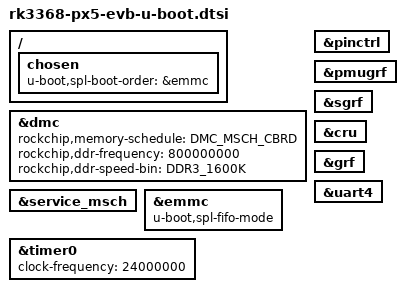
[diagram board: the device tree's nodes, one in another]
// SPDX-License-Identifier: GPL-2.0+ OR X11
/*
 * (C) Copyright 2017 Theobroma Systems Design und Consulting GmbH
 */

#include "rk3368-u-boot.dtsi"

/ {
	chosen {
		u-boot,spl-boot-order = &emmc;
	};
};

&dmc {
	u-boot,dm-all;

	/*
	 * PX5-evb(2GB) need to use CBRD mode, or else the dram is not correct
	 * See doc/device-tree-bindings/clock/rockchip,rk3368-dmc.txt for
	 * details on the 'rockchip,memory-schedule' property and how it
	 * affects the physical-address to device-address mapping.
	 */
	rockchip,memory-schedule = <DMC_MSCH_CBRD>;
	rockchip,ddr-frequency = <800000000>;
	rockchip,ddr-speed-bin = <DDR3_1600K>;

	status = "okay";
};

&pinctrl {
	u-boot,dm-all;
};

&service_msch {
	u-boot,dm-all;
};

&dmc {
	u-boot,dm-all;
	status = "okay";
};

&pmugrf {
	u-boot,dm-all;
};

&sgrf {
	u-boot,dm-all;
};

&cru {
	u-boot,dm-all;
};

&grf {
	u-boot,dm-all;
};

&uart4 {
	u-boot,dm-all;
};

&emmc {
	/* mmc to sram can't do dma, prevent aborts transferring TF-A parts */
	u-boot,spl-fifo-mode;
	u-boot,dm-all;
};

&timer0 {
	u-boot,dm-all;
	clock-frequency = <24000000>;
	status = "okay";
};
